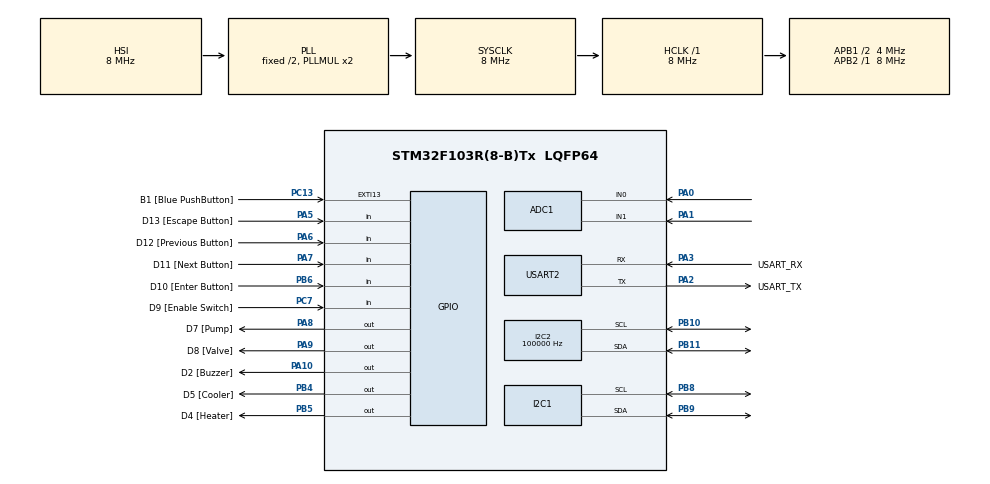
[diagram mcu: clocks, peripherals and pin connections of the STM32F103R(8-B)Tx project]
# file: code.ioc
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ADC1.Channel-1\#ChannelRegularConversion=ADC_CHANNEL_0
ADC1.Channel-2\#ChannelRegularConversion=ADC_CHANNEL_1
ADC1.ContinuousConvMode=DISABLE
ADC1.ExternalTrigConv=ADC_EXTERNALTRIGCONV_T3_TRGO
ADC1.NbrOfConversion=2
ADC1.NbrOfConversionFlag=1
ADC1.Rank-1\#ChannelRegularConversion=1
ADC1.Rank-2\#ChannelRegularConversion=2
ADC1.SamplingTime-1\#ChannelRegularConversion=ADC_SAMPLETIME_55CYCLES_5
ADC1.SamplingTime-2\#ChannelRegularConversion=ADC_SAMPLETIME_55CYCLES_5
ADC1.master=1
Dma.ADC1.0.Direction=DMA_PERIPH_TO_MEMORY
Dma.ADC1.0.Instance=DMA1_Channel1
Dma.ADC1.0.MemDataAlignment=DMA_MDATAALIGN_HALFWORD
Dma.ADC1.0.MemInc=DMA_MINC_ENABLE
Dma.ADC1.0.Mode=DMA_CIRCULAR
Dma.ADC1.0.PeriphDataAlignment=DMA_PDATAALIGN_HALFWORD
Dma.ADC1.0.PeriphInc=DMA_PINC_DISABLE
Dma.ADC1.0.Priority=DMA_PRIORITY_LOW
Dma.Request0=ADC1
I2C2.ClockSpeed=100000
I2C2.I2C_Mode=I2C_Standard
Mcu.Family=STM32F1
Mcu.Name=STM32F103R(8-B)Tx
Mcu.Package=LQFP64
NVIC.ADC1_2_IRQn=true\:0\:0\:false\:false\:true\:true\:true\:true
NVIC.DMA1_Channel1_IRQn=true\:0\:0\:false\:false\:true\:false\:true\:true
NVIC.I2C1_EV_IRQn=true\:0\:0\:false\:false\:true\:true\:true\:true
NVIC.I2C2_ER_IRQn=true\:0\:0\:false\:false\:true\:true\:true\:true
NVIC.I2C2_EV_IRQn=true\:0\:0\:false\:false\:true\:true\:true\:true
NVIC.PriorityGroup=NVIC_PRIORITYGROUP_4
PA0-WKUP.Signal=ADCx_IN0
PA1.Signal=ADCx_IN1
PA10.GPIO_Label=D2 [Buzzer]
PA10.GPIO_PuPd=GPIO_PULLDOWN
PA10.Signal=GPIO_Output
PA13.GPIO_Label=TMS
PA13.Mode=Serial_Wire
PA13.Signal=SYS_JTMS-SWDIO
PA14.GPIO_Label=TCK
PA14.Mode=Serial_Wire
PA14.Signal=SYS_JTCK-SWCLK
PA2.GPIO_Label=USART_TX
PA2.GPIO_Mode=GPIO_MODE_AF_PP
PA2.GPIO_PuPd=GPIO_NOPULL
PA2.GPIO_Speed=GPIO_SPEED_FREQ_LOW
PA2.Mode=Asynchronous
PA2.Signal=USART2_TX
PA3.GPIO_Label=USART_RX
PA3.GPIO_Mode=GPIO_MODE_AF_PP
PA3.GPIO_PuPd=GPIO_NOPULL
PA3.GPIO_Speed=GPIO_SPEED_FREQ_LOW
PA3.Mode=Asynchronous
PA3.Signal=USART2_RX
PA5.GPIO_Label=D13 [Escape Button]
PA5.GPIO_PuPd=GPIO_PULLUP
PA5.Signal=GPIO_Input
PA6.GPIO_Label=D12 [Previous Button]
PA6.GPIO_PuPd=GPIO_PULLUP
PA6.Signal=GPIO_Input
PA7.GPIO_Label=D11 [Next Button]
PA7.GPIO_PuPd=GPIO_PULLUP
PA7.Signal=GPIO_Input
PA8.GPIO_Label=D7 [Pump]
PA8.GPIO_ModeDefaultOutputPP=GPIO_MODE_OUTPUT_OD
PA8.GPIO_PuPd=GPIO_NOPULL
PA8.Signal=GPIO_Output
PA9.GPIO_Label=D8 [Valve]
PA9.GPIO_PuPd=GPIO_PULLDOWN
PA9.Signal=GPIO_Output
PB10.Mode=I2C
PB10.Signal=I2C2_SCL
PB11.Mode=I2C
PB11.Signal=I2C2_SDA
PB3.GPIO_Label=SWO
PB3.Signal=SYS_JTDO-TRACESWO
PB4.GPIO_Label=D5 [Cooler]
PB4.GPIO_PuPd=GPIO_PULLDOWN
PB4.Signal=GPIO_Output
PB5.GPIO_Label=D4 [Heater]
PB5.GPIO_PuPd=GPIO_PULLDOWN
PB5.Signal=GPIO_Output
PB6.GPIO_Label=D10 [Enter Button]
PB6.GPIO_PuPd=GPIO_PULLUP
PB6.Signal=GPIO_Input
PB8.Mode=I2C
PB8.Signal=I2C1_SCL
PB9.Mode=I2C
PB9.Signal=I2C1_SDA
PC13-TAMPER-RTC.GPIO_Label=B1 [Blue PushButton]
PC13-TAMPER-RTC.GPIO_PuPd=GPIO_NOPULL
PC13-TAMPER-RTC.Signal=GPXTI13
PC14-OSC32_IN.Mode=LSE-External-Oscillator
PC14-OSC32_IN.Signal=RCC_OSC32_IN
PC15-OSC32_OUT.Mode=LSE-External-Oscillator
PC15-OSC32_OUT.Signal=RCC_OSC32_OUT
PC7.GPIO_Label=D9 [Enable Switch]
PC7.GPIO_PuPd=GPIO_PULLUP
PC7.Signal=GPIO_Input
PD0-OSC_IN.Mode=HSE-External-Clock-Source
PD0-OSC_IN.Signal=RCC_OSC_IN
PD1-OSC_OUT.Mode=HSE-External-Clock-Source
PD1-OSC_OUT.Signal=RCC_OSC_OUT
ProjectManager.HeapSize=0x200
ProjectManager.StackSize=0x400
ProjectManager.TargetToolchain=STM32CubeIDE
RCC.AHBFreq_Value=8000000
RCC.APB1CLKDivider=RCC_HCLK_DIV2
RCC.APB1Freq_Value=4000000
RCC.APB1TimFreq_Value=8000000
RCC.APB2Freq_Value=8000000
RCC.APB2TimFreq_Value=8000000
RCC.HCLKFreq_Value=8000000
RCC.RTCClockSelection=RCC_RTCCLKSOURCE_LSE
RCC.SYSCLKFreq_VALUE=8000000
RCC.SYSCLKSource=RCC_SYSCLKSOURCE_PLLCLK
RCC.USBFreq_Value=8000000
SH.ADCx_IN0.0=ADC1_IN0,IN0
SH.ADCx_IN1.0=ADC1_IN1,IN1
TIM3.Period=7999
TIM3.Prescaler=0
TIM3.TIM_MasterOutputTrigger=TIM_TRGO_UPDATE
USART2.VirtualMode=VM_ASYNC
VP_TIM3_VS_ClockSourceINT.Mode=Internal
board=NUCLEO-F103RB

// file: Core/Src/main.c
/* USER CODE BEGIN Header */
/**
  ******************************************************************************
  * @file           : main.c
  * @brief          : Main program body
  ******************************************************************************
  * @attention
  *
  * Copyright (c) 2025 STMicroelectronics.
  * All rights reserved.
  *
  * This software is licensed under terms that can be found in the LICENSE file
  * in the root directory of this software component.
  * If no LICENSE file comes with this software, it is provided AS-IS.
  *
  ******************************************************************************
  */
/* USER CODE END Header */
#include "main.h"

/* USER CODE BEGIN Includes */

/* Demo includes. */
#include "logger.h"
#include "dwt.h"

/* Application includes. */
#include "app.h"

/* USER CODE END Includes */

ADC_HandleTypeDef hadc1;
DMA_HandleTypeDef hdma_adc1;

I2C_HandleTypeDef hi2c1;
I2C_HandleTypeDef hi2c2;

TIM_HandleTypeDef htim3;

UART_HandleTypeDef huart2;

void SystemClock_Config(void);
static void MX_GPIO_Init(void);
static void MX_DMA_Init(void);
static void MX_USART2_UART_Init(void);
static void MX_ADC1_Init(void);
static void MX_TIM3_Init(void);
static void MX_I2C1_Init(void);
static void MX_I2C2_Init(void);

/* USER CODE BEGIN 0 */
extern void initialise_monitor_handles(void);

/* USER CODE END 0 */

int main(void)
{

  /* USER CODE BEGIN 1 */
	initialise_monitor_handles();

  /* USER CODE END 1 */

  /* MCU Configuration--------------------------------------------------------*/

  /* Reset of all peripherals, Initializes the Flash interface and the Systick. */
  HAL_Init();

  /* Configure the system clock */
  SystemClock_Config();

  /* Initialize all configured peripherals */
  MX_GPIO_Init();
  MX_DMA_Init();
  MX_USART2_UART_Init();
  MX_ADC1_Init();
  MX_TIM3_Init();
  MX_I2C1_Init();
  MX_I2C2_Init();
  /* USER CODE BEGIN 2 */

  HAL_TIM_Base_Start(&htim3);
	/* Application Init */
	app_init();

  /* USER CODE END 2 */

  /* Infinite loop */
  while (1)
  {

    /* USER CODE BEGIN 3 */

	  /* Application Update */
	  app_update();
  }
  /* USER CODE END 3 */
}

void SystemClock_Config(void)
{
  RCC_OscInitTypeDef RCC_OscInitStruct = {0};
  RCC_ClkInitTypeDef RCC_ClkInitStruct = {0};
  RCC_PeriphCLKInitTypeDef PeriphClkInit = {0};

  /** Initializes the RCC Oscillators according to the specified parameters
  * in the RCC_OscInitTypeDef structure.
  */
  RCC_OscInitStruct.OscillatorType = RCC_OSCILLATORTYPE_HSI;
  RCC_OscInitStruct.HSIState = RCC_HSI_ON;
  RCC_OscInitStruct.HSICalibrationValue = RCC_HSICALIBRATION_DEFAULT;
  RCC_OscInitStruct.PLL.PLLState = RCC_PLL_ON;
  RCC_OscInitStruct.PLL.PLLSource = RCC_PLLSOURCE_HSI_DIV2;
  RCC_OscInitStruct.PLL.PLLMUL = RCC_PLL_MUL2;
  if (HAL_RCC_OscConfig(&RCC_OscInitStruct) != HAL_OK)
  {
    Error_Handler();
  }

  /** Initializes the CPU, AHB and APB buses clocks
  */
  RCC_ClkInitStruct.ClockType = RCC_CLOCKTYPE_HCLK|RCC_CLOCKTYPE_SYSCLK
                              |RCC_CLOCKTYPE_PCLK1|RCC_CLOCKTYPE_PCLK2;
  RCC_ClkInitStruct.SYSCLKSource = RCC_SYSCLKSOURCE_PLLCLK;
  RCC_ClkInitStruct.AHBCLKDivider = RCC_SYSCLK_DIV1;
  RCC_ClkInitStruct.APB1CLKDivider = RCC_HCLK_DIV2;
  RCC_ClkInitStruct.APB2CLKDivider = RCC_HCLK_DIV1;

  if (HAL_RCC_ClockConfig(&RCC_ClkInitStruct, FLASH_LATENCY_0) != HAL_OK)
  {
    Error_Handler();
  }
  PeriphClkInit.PeriphClockSelection = RCC_PERIPHCLK_ADC;
  PeriphClkInit.AdcClockSelection = RCC_ADCPCLK2_DIV2;
  if (HAL_RCCEx_PeriphCLKConfig(&PeriphClkInit) != HAL_OK)
  {
    Error_Handler();
  }
}

static void MX_ADC1_Init(void)
{

  ADC_ChannelConfTypeDef sConfig = {0};

  /** Common config
  */
  hadc1.Instance = ADC1;
  hadc1.Init.ScanConvMode = ADC_SCAN_ENABLE;
  hadc1.Init.ContinuousConvMode = DISABLE;
  hadc1.Init.DiscontinuousConvMode = DISABLE;
  hadc1.Init.ExternalTrigConv = ADC_EXTERNALTRIGCONV_T3_TRGO;
  hadc1.Init.DataAlign = ADC_DATAALIGN_RIGHT;
  hadc1.Init.NbrOfConversion = 2;
  if (HAL_ADC_Init(&hadc1) != HAL_OK)
  {
    Error_Handler();
  }

  /** Configure Regular Channel
  */
  sConfig.Channel = ADC_CHANNEL_0;
  sConfig.Rank = ADC_REGULAR_RANK_1;
  sConfig.SamplingTime = ADC_SAMPLETIME_55CYCLES_5;
  if (HAL_ADC_ConfigChannel(&hadc1, &sConfig) != HAL_OK)
  {
    Error_Handler();
  }

  /** Configure Regular Channel
  */
  sConfig.Channel = ADC_CHANNEL_1;
  sConfig.Rank = ADC_REGULAR_RANK_2;
  if (HAL_ADC_ConfigChannel(&hadc1, &sConfig) != HAL_OK)
  {
    Error_Handler();
  }

}

static void MX_I2C1_Init(void)
{

  hi2c1.Instance = I2C1;
  hi2c1.Init.ClockSpeed = 100000;
  hi2c1.Init.DutyCycle = I2C_DUTYCYCLE_2;
  hi2c1.Init.OwnAddress1 = 0;
  hi2c1.Init.AddressingMode = I2C_ADDRESSINGMODE_7BIT;
  hi2c1.Init.DualAddressMode = I2C_DUALADDRESS_DISABLE;
  hi2c1.Init.OwnAddress2 = 0;
  hi2c1.Init.GeneralCallMode = I2C_GENERALCALL_DISABLE;
  hi2c1.Init.NoStretchMode = I2C_NOSTRETCH_DISABLE;
  if (HAL_I2C_Init(&hi2c1) != HAL_OK)
  {
    Error_Handler();
  }

}

static void MX_I2C2_Init(void)
{

  hi2c2.Instance = I2C2;
  hi2c2.Init.ClockSpeed = 100000;
  hi2c2.Init.DutyCycle = I2C_DUTYCYCLE_2;
  hi2c2.Init.OwnAddress1 = 0;
  hi2c2.Init.AddressingMode = I2C_ADDRESSINGMODE_7BIT;
  hi2c2.Init.DualAddressMode = I2C_DUALADDRESS_DISABLE;
  hi2c2.Init.OwnAddress2 = 0;
  hi2c2.Init.GeneralCallMode = I2C_GENERALCALL_DISABLE;
  hi2c2.Init.NoStretchMode = I2C_NOSTRETCH_DISABLE;
  if (HAL_I2C_Init(&hi2c2) != HAL_OK)
  {
    Error_Handler();
  }

}

static void MX_TIM3_Init(void)
{

  TIM_ClockConfigTypeDef sClockSourceConfig = {0};
  TIM_MasterConfigTypeDef sMasterConfig = {0};

  htim3.Instance = TIM3;
  htim3.Init.Prescaler = 0;
  htim3.Init.CounterMode = TIM_COUNTERMODE_UP;
  htim3.Init.Period = 7999;
  htim3.Init.ClockDivision = TIM_CLOCKDIVISION_DIV1;
  htim3.Init.AutoReloadPreload = TIM_AUTORELOAD_PRELOAD_DISABLE;
  if (HAL_TIM_Base_Init(&htim3) != HAL_OK)
  {
    Error_Handler();
  }
  sClockSourceConfig.ClockSource = TIM_CLOCKSOURCE_INTERNAL;
  if (HAL_TIM_ConfigClockSource(&htim3, &sClockSourceConfig) != HAL_OK)
  {
    Error_Handler();
  }
  sMasterConfig.MasterOutputTrigger = TIM_TRGO_UPDATE;
  sMasterConfig.MasterSlaveMode = TIM_MASTERSLAVEMODE_DISABLE;
  if (HAL_TIMEx_MasterConfigSynchronization(&htim3, &sMasterConfig) != HAL_OK)
  {
    Error_Handler();
  }

}

static void MX_USART2_UART_Init(void)
{

  huart2.Instance = USART2;
  huart2.Init.BaudRate = 115200;
  huart2.Init.WordLength = UART_WORDLENGTH_8B;
  huart2.Init.StopBits = UART_STOPBITS_1;
  huart2.Init.Parity = UART_PARITY_NONE;
  huart2.Init.Mode = UART_MODE_TX_RX;
  huart2.Init.HwFlowCtl = UART_HWCONTROL_NONE;
  huart2.Init.OverSampling = UART_OVERSAMPLING_16;
  if (HAL_UART_Init(&huart2) != HAL_OK)
  {
    Error_Handler();
  }

}

static void MX_DMA_Init(void)
{

  /* DMA controller clock enable */
  __HAL_RCC_DMA1_CLK_ENABLE();

  /* DMA interrupt init */
  /* DMA1_Channel1_IRQn interrupt configuration */
  HAL_NVIC_SetPriority(DMA1_Channel1_IRQn, 0, 0);
  HAL_NVIC_EnableIRQ(DMA1_Channel1_IRQn);

}

static void MX_GPIO_Init(void)
{
  GPIO_InitTypeDef GPIO_InitStruct = {0};

  /* GPIO Ports Clock Enable */
  __HAL_RCC_GPIOC_CLK_ENABLE();
  __HAL_RCC_GPIOD_CLK_ENABLE();
  __HAL_RCC_GPIOA_CLK_ENABLE();
  __HAL_RCC_GPIOB_CLK_ENABLE();

  /*Configure GPIO pin Output Level */
  HAL_GPIO_WritePin(GPIOA, D7_Pin|D8_Pin|D2_Pin, GPIO_PIN_RESET);

  /*Configure GPIO pin Output Level */
  HAL_GPIO_WritePin(GPIOB, D5_Pin|D4_Pin, GPIO_PIN_RESET);

  /*Configure GPIO pin : B1_Pin */
  GPIO_InitStruct.Pin = B1_Pin;
  GPIO_InitStruct.Mode = GPIO_MODE_IT_RISING;
  GPIO_InitStruct.Pull = GPIO_NOPULL;
  HAL_GPIO_Init(B1_GPIO_Port, &GPIO_InitStruct);

  /*Configure GPIO pins : D13_Pin D12_Pin D11_Pin */
  GPIO_InitStruct.Pin = D13_Pin|D12_Pin|D11_Pin;
  GPIO_InitStruct.Mode = GPIO_MODE_INPUT;
  GPIO_InitStruct.Pull = GPIO_PULLUP;
  HAL_GPIO_Init(GPIOA, &GPIO_InitStruct);

  /*Configure GPIO pin : D9_Pin */
  GPIO_InitStruct.Pin = D9_Pin;
  GPIO_InitStruct.Mode = GPIO_MODE_INPUT;
  GPIO_InitStruct.Pull = GPIO_PULLUP;
  HAL_GPIO_Init(D9_GPIO_Port, &GPIO_InitStruct);

  /*Configure GPIO pin : D7_Pin */
  GPIO_InitStruct.Pin = D7_Pin;
  GPIO_InitStruct.Mode = GPIO_MODE_OUTPUT_OD;
  GPIO_InitStruct.Pull = GPIO_NOPULL;
  GPIO_InitStruct.Speed = GPIO_SPEED_FREQ_LOW;
  HAL_GPIO_Init(D7_GPIO_Port, &GPIO_InitStruct);

  /*Configure GPIO pins : D8_Pin D2_Pin */
  GPIO_InitStruct.Pin = D8_Pin|D2_Pin;
  GPIO_InitStruct.Mode = GPIO_MODE_OUTPUT_PP;
  GPIO_InitStruct.Pull = GPIO_PULLDOWN;
  GPIO_InitStruct.Speed = GPIO_SPEED_FREQ_LOW;
  HAL_GPIO_Init(GPIOA, &GPIO_InitStruct);

  /*Configure GPIO pins : D5_Pin D4_Pin */
  GPIO_InitStruct.Pin = D5_Pin|D4_Pin;
  GPIO_InitStruct.Mode = GPIO_MODE_OUTPUT_PP;
  GPIO_InitStruct.Pull = GPIO_PULLDOWN;
  GPIO_InitStruct.Speed = GPIO_SPEED_FREQ_LOW;
  HAL_GPIO_Init(GPIOB, &GPIO_InitStruct);

  /*Configure GPIO pin : D10_Pin */
  GPIO_InitStruct.Pin = D10_Pin;
  GPIO_InitStruct.Mode = GPIO_MODE_INPUT;
  GPIO_InitStruct.Pull = GPIO_PULLUP;
  HAL_GPIO_Init(D10_GPIO_Port, &GPIO_InitStruct);

}

void Error_Handler(void)
{
  __disable_irq();
  while (1)
  {
  }
}
